VERSION ""

NS_ :

BS_:

BU_:

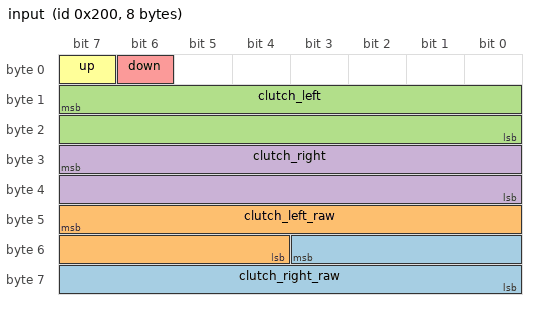
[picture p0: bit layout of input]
BO_ 512 input: 8 Vector__XXX
 SG_ clutch_right_raw : 51|12@0+ (1,0) [0|0] "" Vector__XXX
 SG_ clutch_left_raw : 47|12@0+ (1,0) [0|0] "" Vector__XXX
 SG_ clutch_left : 15|16@0+ (0.01,0) [0|100] "%" Vector__XXX
 SG_ clutch_right : 31|16@0+ (0.01,0) [0|100] "%" Vector__XXX
 SG_ down : 6|1@0+ (1,0) [0|0] "boolean" Vector__XXX
 SG_ up : 7|1@0+ (1,0) [0|0] "boolean" Vector__XXX

BA_DEF_  "BusType" STRING ;
BA_DEF_DEF_  "BusType" "CAN";
